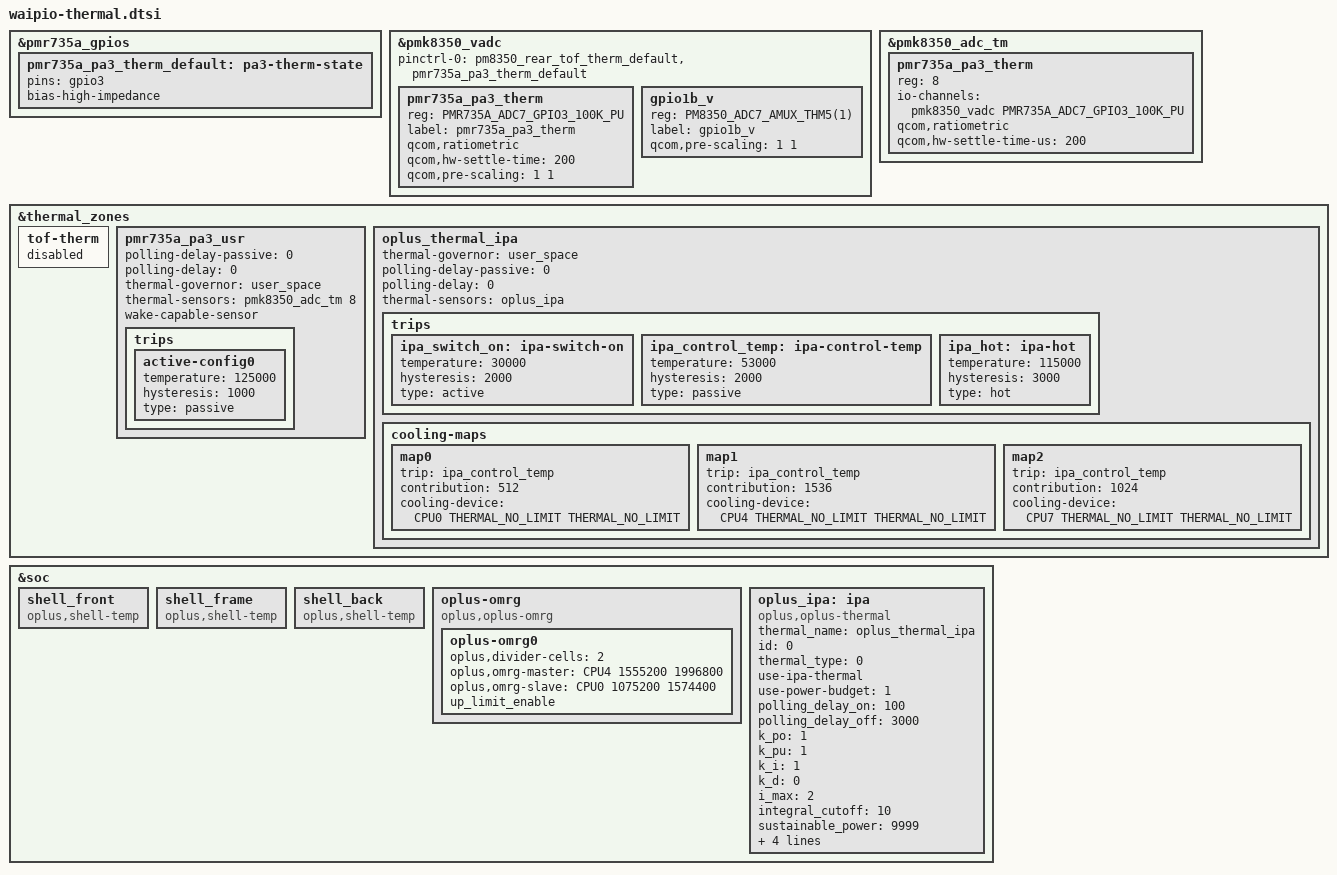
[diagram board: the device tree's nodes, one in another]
// SPDX-License-Identifier: GPL-2.0-only

&pmr735a_gpios {
	pmr735a_pa3_therm_default: pa3-therm-state {
		pins = "gpio3";
		bias-high-impedance;
	};
};

&pmk8350_vadc {
	pinctrl-0 = <&pm8350_rear_tof_therm_default &pmr735a_pa3_therm_default>;

	pmr735a_pa3_therm {
		reg = <PMR735A_ADC7_GPIO3_100K_PU>;
		label = "pmr735a_pa3_therm";
		qcom,ratiometric;
		qcom,hw-settle-time = <200>;
		qcom,pre-scaling = <1 1>;
	};
};

&pmk8350_adc_tm {
	pmr735a_pa3_therm {
		reg = <8>;
		io-channels = <&pmk8350_vadc PMR735A_ADC7_GPIO3_100K_PU>;
		qcom,ratiometric;
		qcom,hw-settle-time-us = <200>;
	};
};

&thermal_zones {
	tof-therm {
		status = "disabled";
	};

	pmr735a_pa3_usr {
		polling-delay-passive = <0>;
		polling-delay = <0>;
		thermal-governor = "user_space";
		thermal-sensors = <&pmk8350_adc_tm 8>;
		wake-capable-sensor;

		trips {
			active-config0 {
				temperature = <125000>;
				hysteresis = <1000>;
				type = "passive";
			};
		};
	};
};

&pmk8350_vadc {
	gpio1b_v {
		reg = <PM8350_ADC7_AMUX_THM5(1)>;
		label = "gpio1b_v";
		qcom,pre-scaling = <1 1>;
	};
};

&soc {
	shell_front {
		compatible = "oplus,shell-temp";
	};
};

&soc {
	shell_frame {
		compatible = "oplus,shell-temp";
	};
};

&soc {
	shell_back {
		compatible = "oplus,shell-temp";
	};
};

&soc {
	oplus-omrg {
		compatible = "oplus,oplus-omrg";
		oplus-omrg0 {
			oplus,divider-cells = <2>;
			oplus,omrg-master = <&CPU4 1555200 1996800>;
			oplus,omrg-slave = <&CPU0 1075200 1574400>;
			up_limit_enable;
			/* down_limit_enable; */
			/* thermal_enable; */
		};
	};
};

&soc {
	oplus_ipa: ipa {
		compatible = "oplus,oplus-thermal";
		thermal_name = "oplus_thermal_ipa";
		id = <0>;
		thermal_type = <0>;
		#thermal-sensor-cells = <0>;
		use-ipa-thermal;
		use-power-budget = <1>;
		polling_delay_on = <100>;
		polling_delay_off = <3000>;
		k_po = <1>;
		k_pu = <1>;
		k_i = <1>;
		k_d = <0>;
		i_max = <2>;
		integral_cutoff = <10>;
		sustainable_power = <9999>;
		thermal_work_affinity = "0-7";
		cdev_min_power = <200 410 210 0 0 0>;
		use-thermalcontrol-limit = <1>;
		clt_state_limit = <0 0 0 0 0 0>;
	};
};

&thermal_zones {
	oplus_thermal_ipa {
		thermal-governor = "user_space";
		polling-delay-passive = <0>;
		polling-delay = <0>;
		thermal-sensors = <&oplus_ipa>;
		trips {
			ipa_switch_on: ipa-switch-on {
				temperature = <30000>;
				hysteresis = <2000>;
				type = "active";
			};
			ipa_control_temp: ipa-control-temp {
				temperature = <53000>;
				hysteresis = <2000>;
				type = "passive";
			};
			ipa_hot: ipa-hot {
				temperature = <115000>;
				hysteresis = <3000>;
				type = "hot";
			};
		};
		cooling-maps {
			map0 {
				trip = <&ipa_control_temp>;
				contribution = <512>;
				cooling-device = <&CPU0 THERMAL_NO_LIMIT THERMAL_NO_LIMIT>;
			};
			map1 {
				trip = <&ipa_control_temp>;
				contribution = <1536>;
				cooling-device = <&CPU4 THERMAL_NO_LIMIT THERMAL_NO_LIMIT>;
			};
			map2 {
				trip = <&ipa_control_temp>;
				contribution = <1024>;
				cooling-device = <&CPU7 THERMAL_NO_LIMIT THERMAL_NO_LIMIT>;
			};
		};
	};
};
